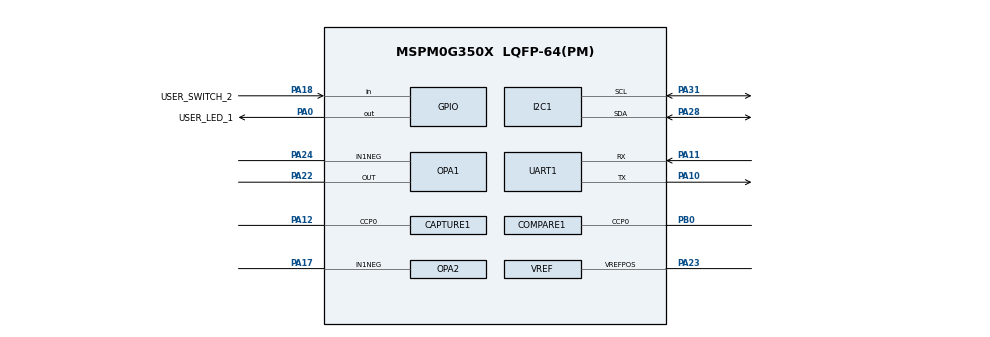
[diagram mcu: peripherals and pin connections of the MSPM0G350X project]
/**
 * @cliArgs --device "MSPM0G350X" --part "Default" --package "LQFP-64(PM)" --product "mspm0_sdk@2.04.00.06"
 * @versions {"tool":"1.23.0+4000"}
 */

/**
 * Import the modules used in this configuration.
 */
const ADC12         = scripting.addModule("/ti/driverlib/ADC12", {}, false);
const ADC121        = ADC12.addInstance();
const ADC122        = ADC12.addInstance();
const Board         = scripting.addModule("/ti/driverlib/Board");
const CAPTURE       = scripting.addModule("/ti/driverlib/CAPTURE", {}, false);
const CAPTURE1      = CAPTURE.addInstance();
const COMP          = scripting.addModule("/ti/driverlib/COMP", {}, false);
const COMP1         = COMP.addInstance();
const COMP2         = COMP.addInstance();
const COMP3         = COMP.addInstance();
const COMPARE       = scripting.addModule("/ti/driverlib/COMPARE", {}, false);
const COMPARE1      = COMPARE.addInstance();
const GPIO          = scripting.addModule("/ti/driverlib/GPIO", {}, false);
const GPIO1         = GPIO.addInstance();
const GPIO2         = GPIO.addInstance();
const I2C           = scripting.addModule("/ti/driverlib/I2C", {}, false);
const I2C1          = I2C.addInstance();
const OPA           = scripting.addModule("/ti/driverlib/OPA", {}, false);
const OPA1          = OPA.addInstance();
const OPA2          = OPA.addInstance();
const SYSCTL        = scripting.addModule("/ti/driverlib/SYSCTL");
const TIMER         = scripting.addModule("/ti/driverlib/TIMER", {}, false);
const TIMER1        = TIMER.addInstance();
const TIMER2        = TIMER.addInstance();
const TIMER3        = TIMER.addInstance();
const UART          = scripting.addModule("/ti/driverlib/UART", {}, false);
const UART1         = UART.addInstance();
const VREF          = scripting.addModule("/ti/driverlib/VREF");
const ProjectConfig = scripting.addModule("/ti/project_config/ProjectConfig");

/**
 * Write custom configuration values to the imported modules.
 */
const gate8  = system.clockTree["MFPCLKGATE"];
gate8.enable = true;

ADC121.$name                             = "ADC12_0";
ADC121.repeatMode                        = true;
ADC121.powerDownMode                     = "DL_ADC12_POWER_DOWN_MODE_MANUAL";
ADC121.trigSrc                           = "DL_ADC12_TRIG_SRC_EVENT";
ADC121.subChanID                         = 1;
ADC121.adcMem0trig                       = "DL_ADC12_TRIGGER_MODE_TRIGGER_NEXT";
ADC121.configureDMA                      = true;
ADC121.enabledInterrupts                 = ["DL_ADC12_INTERRUPT_DMA_DONE"];
ADC121.sampCnt                           = 1;
ADC121.enabledDMATriggers                = ["DL_ADC12_DMA_MEM0_RESULT_LOADED"];
ADC121.sampleTime0                       = "62.5ns";
ADC121.interruptPriority                 = "3";
ADC121.peripheral.$assign                = "ADC0";
ADC121.peripheral.adcPin0.$assign        = "PA27";
ADC121.adcPin0Config.$name               = "ti_driverlib_gpio_GPIOPinGeneric0";
ADC121.DMA_CHANNEL.$name                 = "DMA_CH0";
ADC121.DMA_CHANNEL.transferMode          = "FULL_CH_REPEAT_SINGLE";
ADC121.DMA_CHANNEL.addressMode           = "f2b";
ADC121.DMA_CHANNEL.srcLength             = "HALF_WORD";
ADC121.DMA_CHANNEL.dstLength             = "HALF_WORD";
ADC121.DMA_CHANNEL.configureTransferSize = true;
ADC121.DMA_CHANNEL.transferSize          = 1024;

ADC122.$name                             = "ADC12_1";
ADC122.repeatMode                        = true;
ADC122.adcMem0trig                       = "DL_ADC12_TRIGGER_MODE_TRIGGER_NEXT";
ADC122.trigSrc                           = "DL_ADC12_TRIG_SRC_EVENT";
ADC122.powerDownMode                     = "DL_ADC12_POWER_DOWN_MODE_MANUAL";
ADC122.sampleTime0                       = "62.5ns";
ADC122.enabledInterrupts                 = ["DL_ADC12_INTERRUPT_DMA_DONE"];
ADC122.interruptPriority                 = "3";
ADC122.configureDMA                      = true;
ADC122.sampCnt                           = 1;
ADC122.enabledDMATriggers                = ["DL_ADC12_DMA_MEM0_RESULT_LOADED"];
ADC122.subChanID                         = 2;
ADC122.peripheral.$assign                = "ADC1";
ADC122.peripheral.adcPin0.$assign        = "PA15";
ADC122.adcPin0Config.$name               = "ti_driverlib_gpio_GPIOPinGeneric13";
ADC122.DMA_CHANNEL.$name                 = "DMA_CH1";
ADC122.DMA_CHANNEL.addressMode           = "f2b";
ADC122.DMA_CHANNEL.srcLength             = "HALF_WORD";
ADC122.DMA_CHANNEL.dstLength             = "HALF_WORD";
ADC122.DMA_CHANNEL.configureTransferSize = true;
ADC122.DMA_CHANNEL.transferMode          = "FULL_CH_REPEAT_SINGLE";
ADC122.DMA_CHANNEL.transferSize          = 4096;


CAPTURE1.$name                      = "CAPTURE_0";
CAPTURE1.timerPeriod                = "8ms";
CAPTURE1.captMode                   = "COMBINED";
CAPTURE1.interrupts                 = ["CC1_DN","ZERO"];
CAPTURE1.timerClkPrescale           = 32;
CAPTURE1.peripheral.$assign         = "TIMG0";
CAPTURE1.peripheral.ccp0Pin.$assign = "PA12";
CAPTURE1.ccp0PinConfig.$name        = "ti_driverlib_gpio_GPIOPinGeneric3";

COMP1.$name              = "COMP_0";
COMP1.controlSelect      = "DL_COMP_DAC_CONTROL_SW";
COMP1.vSource            = "DL_COMP_REF_SOURCE_VREF_DAC";
COMP1.setDACCode0        = 0x49;
COMP1.peripheral.$assign = "COMP0";

COMP2.$name              = "COMP_1";
COMP2.selectOutputFilter = "DL_COMP_FILTER_DELAY_1200";
COMP2.vSource            = "DL_COMP_REF_SOURCE_VREF_DAC";
COMP2.controlSelect      = "DL_COMP_DAC_CONTROL_SW";
COMP2.setDACCode0        = 0x49;
COMP2.peripheral.$assign = "COMP1";

COMP3.$name                          = "COMP_2";
COMP3.channelEnable                  = ["NEG","POS"];
COMP3.outputEnable                   = true;
COMP3.hysteresis                     = "DL_COMP_HYSTERESIS_20";
COMP3.enableOutputFilter             = true;
COMP3.selectOutputFilter             = "DL_COMP_FILTER_DELAY_1200";
COMP3.compPinPos0Config.$name        = "ti_driverlib_gpio_GPIOPinGeneric16";
COMP3.compPinNeg0Config.$name        = "ti_driverlib_gpio_GPIOPinGeneric17";
COMP3.peripheral.$assign             = "COMP2";
COMP3.peripheral.compPinOut.$assign  = "PB27";
COMP3.peripheral.compPinPos0.$assign = "PB21";
COMP3.peripheral.compPinNeg0.$assign = "PB22";
COMP3.compPinOutConfig.$name         = "ti_driverlib_gpio_GPIOPinGeneric18";

COMPARE1.$name                      = "COMPARE_0";
COMPARE1.compareMode                = "EDGE_COUNT_UP";
COMPARE1.timerPeriod                = 65535;
COMPARE1.timerClkDiv                = 8;
COMPARE1.timerClkPrescale           = 200;
COMPARE1.peripheral.$assign         = "TIMA1";
COMPARE1.peripheral.ccp0Pin.$assign = "PB0";
COMPARE1.ccp0PinConfig.$name        = "ti_driverlib_gpio_GPIOPinGeneric9";

GPIO1.$name                               = "GPIO_SWITCHES";
GPIO1.associatedPins[0].$name             = "USER_SWITCH_2";
GPIO1.associatedPins[0].internalResistor  = "PULL_UP";
GPIO1.associatedPins[0].direction         = "INPUT";
GPIO1.associatedPins[0].assignedPort      = "PORTA";
GPIO1.associatedPins[0].assignedPin       = "18";
GPIO1.associatedPins[0].interruptPriority = "0";
GPIO1.associatedPins[0].polarity          = "RISE_FALL";
GPIO1.associatedPins[0].pin.$assign       = "PA18";

GPIO2.$name                          = "GPIO_LEDS";
GPIO2.associatedPins[0].$name        = "USER_LED_1";
GPIO2.associatedPins[0].initialValue = "SET";
GPIO2.associatedPins[0].assignedPort = "PORTA";
GPIO2.associatedPins[0].assignedPin  = "0";
GPIO2.associatedPins[0].pin.$assign  = "PA0";

I2C1.$name                             = "I2C_OLED";
I2C1.basicEnableController             = true;
I2C1.intController                     = ["ARBITRATION_LOST","NACK","RXFIFO_TRIGGER","RX_DONE","TX_DONE"];
I2C1.peripheral.$assign                = "I2C0";
I2C1.peripheral.sdaPin.$assign         = "PA28";
I2C1.peripheral.sclPin.$assign         = "PA31";
I2C1.sdaPinConfig.hideOutputInversion  = scripting.forceWrite(false);
I2C1.sdaPinConfig.onlyInternalResistor = scripting.forceWrite(false);
I2C1.sdaPinConfig.passedPeripheralType = scripting.forceWrite("Digital");
I2C1.sdaPinConfig.$name                = "ti_driverlib_gpio_GPIOPinGeneric1";
I2C1.sclPinConfig.hideOutputInversion  = scripting.forceWrite(false);
I2C1.sclPinConfig.onlyInternalResistor = scripting.forceWrite(false);
I2C1.sclPinConfig.passedPeripheralType = scripting.forceWrite("Digital");
I2C1.sclPinConfig.$name                = "ti_driverlib_gpio_GPIOPinGeneric2";

OPA1.$name                            = "OPA_0";
OPA1.cfg0NSELChannel                  = "RTAP";
OPA1.cfg0MSELChannel                  = "IN1_NEG";
OPA1.cfg0Gain                         = "N3_P4";
OPA1.advBW                            = "HIGH";
OPA1.cfg0PSELChannel                  = "DAC8_OUT";
OPA1.cfg0Chop                         = "ADC_AVERAGING";
OPA1.cfg0OutputPin                    = "ENABLED";
OPA1.In1NegPinConfig.$name            = "ti_driverlib_gpio_GPIOPinGeneric7";
OPA1.In1NegPinConfig.enableConfig     = true;
OPA1.In1NegPinConfig.internalResistor = "PULL_UP";
OPA1.peripheral.$assign               = "OPA0";
OPA1.peripheral.In1NegPin.$assign     = "PA24";
OPA1.peripheral.OutPin.$assign        = "PA22";
OPA1.OutPinConfig.$name               = "ti_driverlib_gpio_GPIOPinGeneric8";

OPA2.$name                                   = "OPA_1";
OPA2.cfg0PSELChannel                         = "DAC8_OUT";
OPA2.cfg0NSELChannel                         = "RTAP";
OPA2.cfg0MSELChannel                         = "IN1_NEG";
OPA2.cfg0Gain                                = "N3_P4";
OPA2.cfg0OutputPin                           = "ENABLED";
OPA2.cfg0Chop                                = "ADC_AVERAGING";
OPA2.advBW                                   = "HIGH";
OPA2.In1NegPinConfig.$name                   = "ti_driverlib_gpio_GPIOPinGeneric14";
OPA2.peripheral.$assign                      = "OPA1";
OPA2.peripheral.In1NegPin.$assign            = "PA17";
OPA2.peripheral.OutPin.$assignAllowConflicts = "PA16";
OPA2.OutPinConfig.$name                      = "ti_driverlib_gpio_GPIOPinGeneric15";

SYSCTL.forceDefaultClkConfig = true;
SYSCTL.clockTreeEn           = true;
SYSCTL.MFPCLKEn              = true;

TIMER1.$name                       = "TIMER_0";
TIMER1.timerMode                   = "PERIODIC";
TIMER1.timerStartTimer             = true;
TIMER1.event1PublisherChannel      = 1;
TIMER1.event1ControllerInterruptEn = ["ZERO_EVENT"];
TIMER1.timerPeriod                 = "4us";

TIMER2.$name              = "TIMER_1";
TIMER2.timerClkPrescale   = 256;
TIMER2.timerClkDiv        = 2;
TIMER2.timerMode          = "PERIODIC";
TIMER2.interrupts         = ["ZERO"];
TIMER2.timerPeriod        = "1s";
TIMER2.peripheral.$assign = "TIMA0";

TIMER3.$name                       = "TIMER_2";
TIMER3.timerMode                   = "PERIODIC";
TIMER3.timerStartTimer             = true;
TIMER3.event1PublisherChannel      = 2;
TIMER3.event1ControllerInterruptEn = ["ZERO_EVENT"];
TIMER3.timerPeriod                 = "1ms";

UART1.$name                    = "UART_0";
UART1.enableFIFO               = true;
UART1.peripheral.$assign       = "UART0";
UART1.peripheral.rxPin.$assign = "PA11";
UART1.peripheral.txPin.$assign = "PA10";
UART1.txPinConfig.$name        = "ti_driverlib_gpio_GPIOPinGeneric4";
UART1.rxPinConfig.$name        = "ti_driverlib_gpio_GPIOPinGeneric5";

VREF.checkVREFReady                = true;
VREF.advClockConfigEnable          = true;
VREF.advClkSrc                     = "DL_VREF_CLOCK_BUSCLK";
VREF.peripheral.$assign            = "VREF";
VREF.peripheral.vrefPosPin.$assign = "PA23";
VREF.vrefPosPinConfig.$name        = "ti_driverlib_gpio_GPIOPinGeneric6";

ProjectConfig.genLibCMSIS = true;

/**
 * Pinmux solution for unlocked pins/peripherals. This ensures that minor changes to the automatic solver in a future
 * version of the tool will not impact the pinmux you originally saw.  These lines can be completely deleted in order to
 * re-solve from scratch.
 */
ADC121.DMA_CHANNEL.peripheral.$suggestSolution = "DMA_CH1";
ADC122.DMA_CHANNEL.peripheral.$suggestSolution = "DMA_CH0";
Board.peripheral.$suggestSolution              = "DEBUGSS";
Board.peripheral.swclkPin.$suggestSolution     = "PA20";
Board.peripheral.swdioPin.$suggestSolution     = "PA19";
TIMER1.peripheral.$suggestSolution             = "TIMG7";
TIMER3.peripheral.$suggestSolution             = "TIMG6";
